VERSION "04/12/2025"

NS_ :

BS_:

BU_: RaceCapture

BO_ 171 InverterState: 8 RaceCapture
    SG_ INVState        : 32|32@1+ (1,0)        [0|4294967295]     ""      RaceCapture

BO_ 406385536 ThermistorExpansion: 8 RaceCapture
    SG_ ThermVal        : 16|8@1-  (1,0)        [-40|80]           "C"     RaceCapture
    SG_ ThermID         : 32|8@1+  (1,0)        [1|80]             ""      RaceCapture
    SG_ ThermMax        : 40|8@1-  (1,0)        [-40|80]           "C"     RaceCapture
    SG_ ThermMaxID      : 48|8@1+  (1,0)        [1|80]             ""      RaceCapture
    SG_ ThermMin        : 36|8@1-  (1,0)        [-40|80]           "C"     RaceCapture
    SG_ ThermMinID      : 56|8@1+  (1,0)        [1|80]             ""      RaceCapture

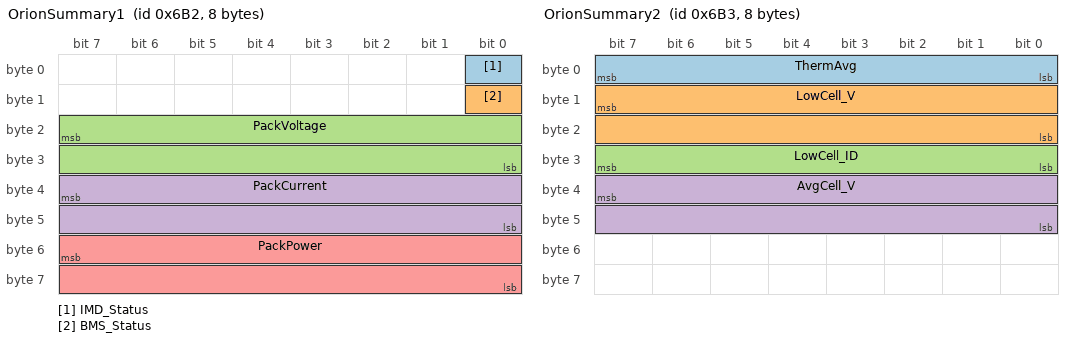
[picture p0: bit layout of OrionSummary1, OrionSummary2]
BO_ 1714 OrionSummary1: 8 RaceCapture
    SG_ IMD_Status      :  0|1@1+  (1,0)        [0|1]              ""      RaceCapture
    SG_ BMS_Status      :  8|1@1+  (1,0)        [0|1]              ""      RaceCapture
    SG_ PackVoltage     : 23|16@0+ (0.1,0)      [0|6553.5]         "V"     RaceCapture
    SG_ PackCurrent     : 39|16@0+ (0.1,0)      [0|6553.5]         "A"     RaceCapture
    SG_ PackPower       : 55|16@0+ (0.1,0)      [0|6553.5]         "kW"    RaceCapture

BO_ 1715 OrionSummary2: 8 RaceCapture
    SG_ ThermAvg        :  7|8@0+  (1,0)        [-40|80]           "C"     RaceCapture
    SG_ LowCell_V       : 15|16@0+ (1.0E-4,0)   [0|6.5535]         "V"     RaceCapture
    SG_ LowCell_ID      : 31|8@0+  (1,0)        [0|80]             ""      RaceCapture
    SG_ AvgCell_V       : 39|16@0+ (1.0E-4,0)   [0|6.5535]         "V"     RaceCapture

BO_ 167 InverterElectrical: 8 RaceCapture
    SG_ OutputV         : 16|16@1- (0.1,0)      [-3276.8|3276.7]   "V"     RaceCapture

BO_ 172 InverterTorque: 8 RaceCapture
    SG_ Torque          : 32|16@1- (0.1,0)      [-3276.8|3276.7]   "Nm"    RaceCapture

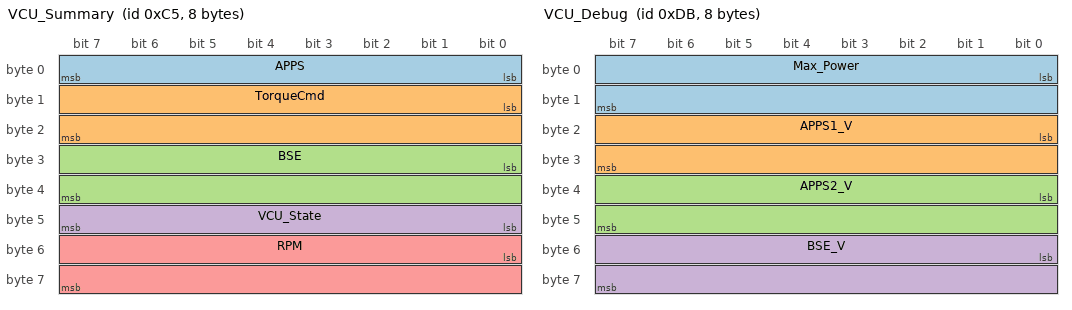
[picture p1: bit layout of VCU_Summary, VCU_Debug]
BO_ 197 VCU_Summary: 8 RaceCapture
    SG_ APPS            :  0|8@1+  (1,0)        [0|100]            "%"     RaceCapture
    SG_ TorqueCmd       :  8|16@1+ (0.1,0)      [0|65535]          "Nm"    RaceCapture
    SG_ BSE             : 24|16@1+ (1,0)        [0|5000]           "psi"   RaceCapture
    SG_ VCU_State       : 40|8@1+  (1,0)        [0|4]              ""      RaceCapture
    SG_ RPM             : 48|16@1- (1,0)        [-32768|32767]     "RPM"   RaceCapture

BO_ 219 VCU_Debug: 8 RaceCapture
    SG_ Max_Power       :  0|16@1- (0.1,0)      [0|6553.5]         "kW"    RaceCapture
    SG_ APPS1_V         : 16|16@1+ (1,0)        [0|5000]           "mV"    RaceCapture
    SG_ APPS2_V         : 32|16@1+ (1,0)        [0|5000]           "mV"    RaceCapture
    SG_ BSE_V           : 48|16@1+ (1,0)        [0|5000]           "mV"    RaceCapture

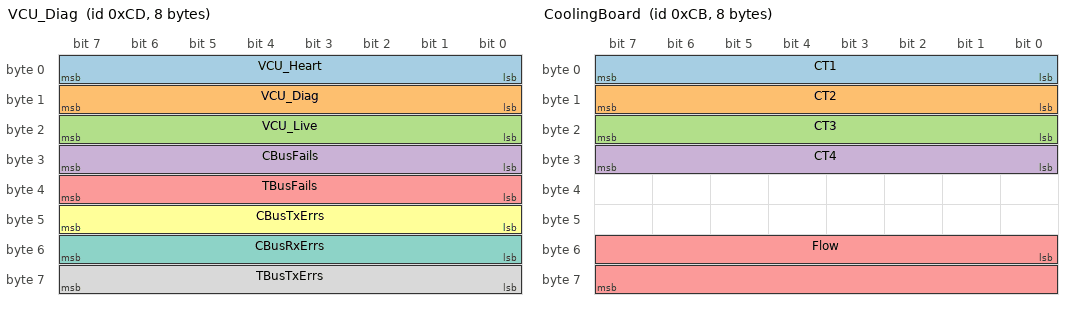
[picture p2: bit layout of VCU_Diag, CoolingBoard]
BO_ 205 VCU_Diag: 8 RaceCapture
    SG_ VCU_Heart       :  0|8@1+  (1,0)       [0|255]             ""      RaceCapture
    SG_ VCU_Diag        :  8|8@1+  (1,0)       [0|255]             ""      RaceCapture
    SG_ VCU_Live        : 16|8@1+  (1,0)       [0|255]             ""      RaceCapture
    SG_ CBusFails       : 24|8@1+  (1,0)       [0|255]             ""      RaceCapture
    SG_ TBusFails       : 32|8@1+  (1,0)       [0|255]             ""      RaceCapture
    SG_ CBusTxErrs      : 40|8@1+  (1,0)       [0|255]             ""      RaceCapture
    SG_ CBusRxErrs      : 48|8@1+  (1,0)       [0|255]             ""      RaceCapture
    SG_ TBusTxErrs      : 56|8@1+  (1,0)       [0|255]             ""      RaceCapture

BO_ 203 CoolingBoard: 8 RaceCapture
    SG_ CT1             :  0|8@1-  (1,0)        [-40|120]          "C"     RaceCapture
    SG_ CT2             :  8|8@1-  (1,0)        [-40|120]          "C"     RaceCapture
    SG_ CT3             : 16|8@1-  (1,0)        [-40|120]          "C"     RaceCapture
    SG_ CT4             : 24|8@1-  (1,0)        [-40|120]          "C"     RaceCapture
    SG_ Flow            : 48|16@1+ (0.1,0)      [0|30]             "L/min" RaceCapture

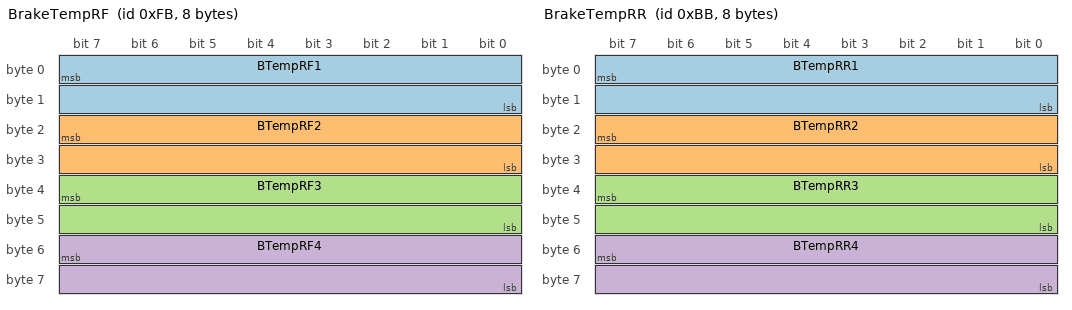
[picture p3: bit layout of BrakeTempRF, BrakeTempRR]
BO_ 251 BrakeTempRF: 8 RaceCapture
    SG_ BTempRF1        :  7|16@0+ (0.1,-100)   [-20|300]          "C"     RaceCapture
    SG_ BTempRF2        : 23|16@0+ (0.1,-100)   [-20|300]          "C"     RaceCapture
    SG_ BTempRF3        : 39|16@0+ (0.1,-100)   [-20|300]          "C"     RaceCapture
    SG_ BTempRF4        : 55|16@0+ (0.1,-100)   [-20|300]          "C"     RaceCapture

BO_ 187 BrakeTempRR: 8 RaceCapture
    SG_ BTempRR1        :  7|16@0+ (0.1,-100)   [-20|300]          "C"     RaceCapture
    SG_ BTempRR2        : 23|16@0+ (0.1,-100)   [-20|300]          "C"     RaceCapture
    SG_ BTempRR3        : 39|16@0+ (0.1,-100)   [-20|300]          "C"     RaceCapture
    SG_ BTempRR4        : 55|16@0+ (0.1,-100)   [-20|300]          "C"     RaceCapture

BO_
